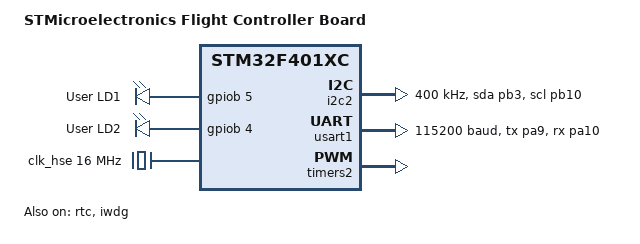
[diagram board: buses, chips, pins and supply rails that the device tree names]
/*
 * Copyright (c) 2019 Linumiz
 *
 * SPDX-License-Identifier: Apache-2.0
 */

/dts-v1/;
#include <st/f4/stm32f401Xc.dtsi>
#include <st/f4/stm32f401c(b-c)ux-pinctrl.dtsi>

/ {
	model = "STMicroelectronics Flight Controller Board";
	compatible = "st,flight-controller-board";

	chosen {
		zephyr,console = &usart1;
		zephyr,shell-uart = &usart1;
		zephyr,sram = &sram0;
		zephyr,flash = &flash0;
	};

	leds {
		compatible = "gpio-leds";
		red_led_1: led_1 {
			gpios = <&gpiob 5 GPIO_ACTIVE_HIGH>;
			label = "User LD1";
		};

		red_led_2: led_2 {
			gpios = <&gpiob 4 GPIO_ACTIVE_HIGH>;
			label = "User LD2";
		};
	};

	aliases {
		led0 = &red_led_1;
		led1 = &red_led_2;
	};
};

&clk_hse {
	clock-frequency = <DT_FREQ_M(16)>;
	status = "okay";
};

&pll {
	div-m = <16>;
	mul-n = <336>;
	div-p = <4>;
	div-q = <7>;
	clocks = <&clk_hse>;
	status = "okay";
};

&rcc {
	clocks = <&pll>;
	clock-frequency = <DT_FREQ_M(84)>;
	ahb-prescaler = <1>;
	apb1-prescaler = <2>;
	apb2-prescaler = <1>;
};

&i2c2 {
	pinctrl-0 = <&i2c2_sda_pb3 &i2c2_scl_pb10>;
	pinctrl-names = "default";
	status = "okay";
	clock-frequency = <I2C_BITRATE_FAST>;
};

&usart1 {
	pinctrl-0 = <&usart1_tx_pa9 &usart1_rx_pa10>;
	pinctrl-names = "default";
	current-speed = <115200>;
	status = "okay";
};

&timers2 {
	status = "okay";

	pwm2: pwm {
		status = "okay";
		pinctrl-0 = <&tim2_ch1_pa0>;
		pinctrl-names = "default";
	};
};

&rtc {
	status = "okay";
};

&iwdg {
	status = "okay";
};
